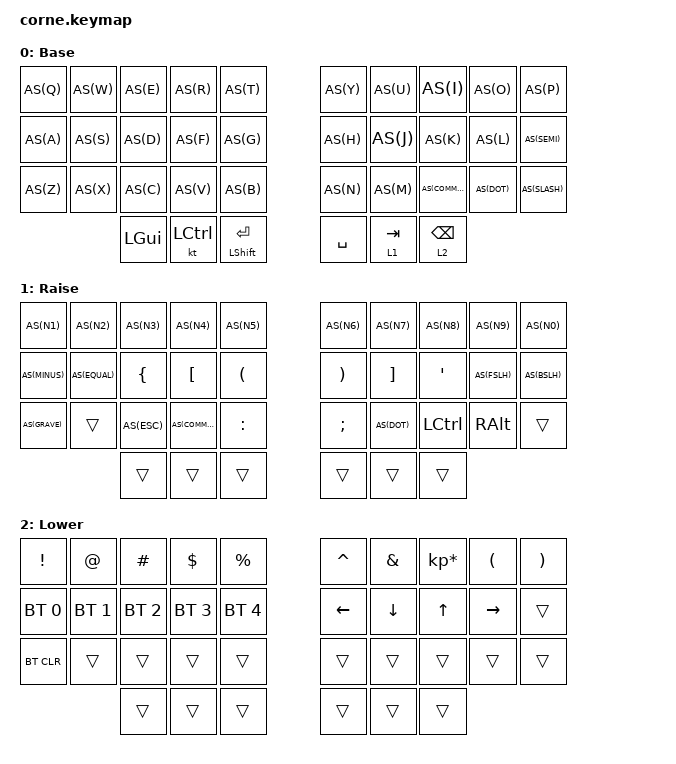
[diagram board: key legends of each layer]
/*
 * Copyright (c) 2020 The ZMK Contributors
 *
 * SPDX-License-Identifier: MIT
 */

#include <behaviors.dtsi>
#include <dt-bindings/zmk/keys.h>
#include <dt-bindings/zmk/bt.h>


#define AS(keycode) &as LS(keycode) keycode

/ {
    chosen {
        zmk,physical-layout = &foostan_corne_5col_layout;
    };

        keymap {
                compatible = "zmk,keymap";

                default_layer {
// -----------------------------------------------------------------------------------------
// |  Q  |  W  |  E  |  R  |  T  |     |  Y  |  U   |  I   |  O   | P |
// |  A  |  S  |  D  |  F  |  G  |     |  H  |  J   |  K   |  L   | ;:| 
// |  Z  |  X  |  C  |  V  |  B  |     |  N  |  M   | ,<   | .>   | /?|
//             | GUI | CTRL| RET/SHFT|     | SPC | TB/2 | BSPC/1 |
                        display-name = "Base";
                        bindings = <
   AS(Q) AS(W) AS(E) AS(R) AS(T)          AS(Y)   AS(U)  AS(I)     AS(O)     AS(P)
   AS(A) AS(S) AS(D) AS(F) AS(G)          AS(H)   AS(J)  AS(K)     AS(L)     AS(SEMI)
   AS(Z) AS(X) AS(C) AS(V) AS(B)          AS(N)   AS(M)  AS(COMMA)  AS(DOT)  AS(SLASH)
				&kp LGUI &kt LCTRL &mt LSHIFT RET &kp SPACE  &lt 1 TAB  &lt 2 BSPC
                        >;
                };

                raise_layer {
// -----------------------------------------------------------------------------------------
// | 1! |  2@ |  3# |  4$ |  5% |     |  6^ |  7& |  8* |  9(  |  0)  |
// | -_ |  =+ |  {  |  [  |  (  |     |  )  |  ]  |  }  |  '"  |  \|  |
// | `~ |     | ESC |  ,< |  :  |     |  ;  |  .> | CTRL| META |      |
//             | GUI | CTRL| RET/SHFT|     | SPC | TB/2 | BSPC/1 |
                        display-name = "Raise";
                        bindings = <

   AS(N1)    AS(N2)    AS(N3)    AS(N4)    AS(N5)        AS(N6)    AS(N7)    AS(N8)    AS(N9)   AS(N0)
   AS(MINUS) AS(EQUAL) &kp LBRC  &kp LBKT  &kp LPAR      &kp RPAR  &kp RBKT  &kp SQT  AS(FSLH) AS(BSLH)
   AS(GRAVE) &trans    AS(ESC)    AS(COMMA) &kp COLON     &kp SEMI  AS(DOT)   &kp LCTRL &kp RALT &trans
                       &trans    &trans    &trans        &trans    &trans     &trans
                        >;
                };

                lower_layer {
// -----------------------------------------------------------------------------------------
// | !     |  @  |  #  |  $  |  %  |     |  ^  |  &  |  *  |  (  |  )  |
// | BT1   | BT2 | BT3 | BT4 | BT5 |     | LFT | DWN |  UP | RGT |     |
// | BTCLR |     |     |     |     |     |     |     |     |     |     |
//             | GUI | CTRL| RET/SHFT|     | SPC | TB/2 | BSPC/1 |
                        display-name = "Lower";
                        bindings = <
   &kp EXCL     &kp AT       &kp HASH     &kp DLLR     &kp PRCNT        &kp CARET &kp AMPS  &kp KP_MULTIPLY &kp LPAR  &kp RPAR
   &bt BT_SEL 0 &bt BT_SEL 1 &bt BT_SEL 2 &bt BT_SEL 3 &bt BT_SEL 4     &kp LEFT  &kp DOWN  &kp UP          &kp RIGHT &trans 
   &bt BT_CLR   &trans       &trans       &trans       &trans           &trans    &trans    &trans          &trans    &trans 
                       &trans    &trans    &trans        &trans    &trans     &trans
                        >;
                };


                extra_1 {
                        status = "reserved";
                };

                extra_2 {
                        status = "reserved";
                };

                extra_3 {
                        status = "reserved";
                };
        };
};
